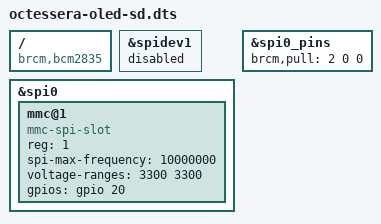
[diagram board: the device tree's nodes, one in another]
/dts-v1/;
/plugin/;

/ {
    compatible = "brcm,bcm2835";

    fragment@0 {
        target = <&spidev1>;
        __overlay__ {
            status = "disabled";
        };
    };

    fragment@1 {
        target = <&spi0>;
        __overlay__ {
            #address-cells = <1>;
            #size-cells = <0>;
            status = "okay";

            mmc@1 {
                compatible = "mmc-spi-slot";
                reg = <1>;
                spi-max-frequency = <10000000>;
                voltage-ranges = <3300 3300>;
                /* Card detect on GPIO20, high when a card is present, pull-up. */
                gpios = <&gpio 20 0x10>;
            };
        };
    };

    /* MISO pull-up: the default pull-down makes an empty slot answer the
     * card status check with zeros, so removal is never detected. */
    fragment@2 {
        target = <&spi0_pins>;
        __overlay__ {
            brcm,pull = <2 0 0>;
        };
    };
};
